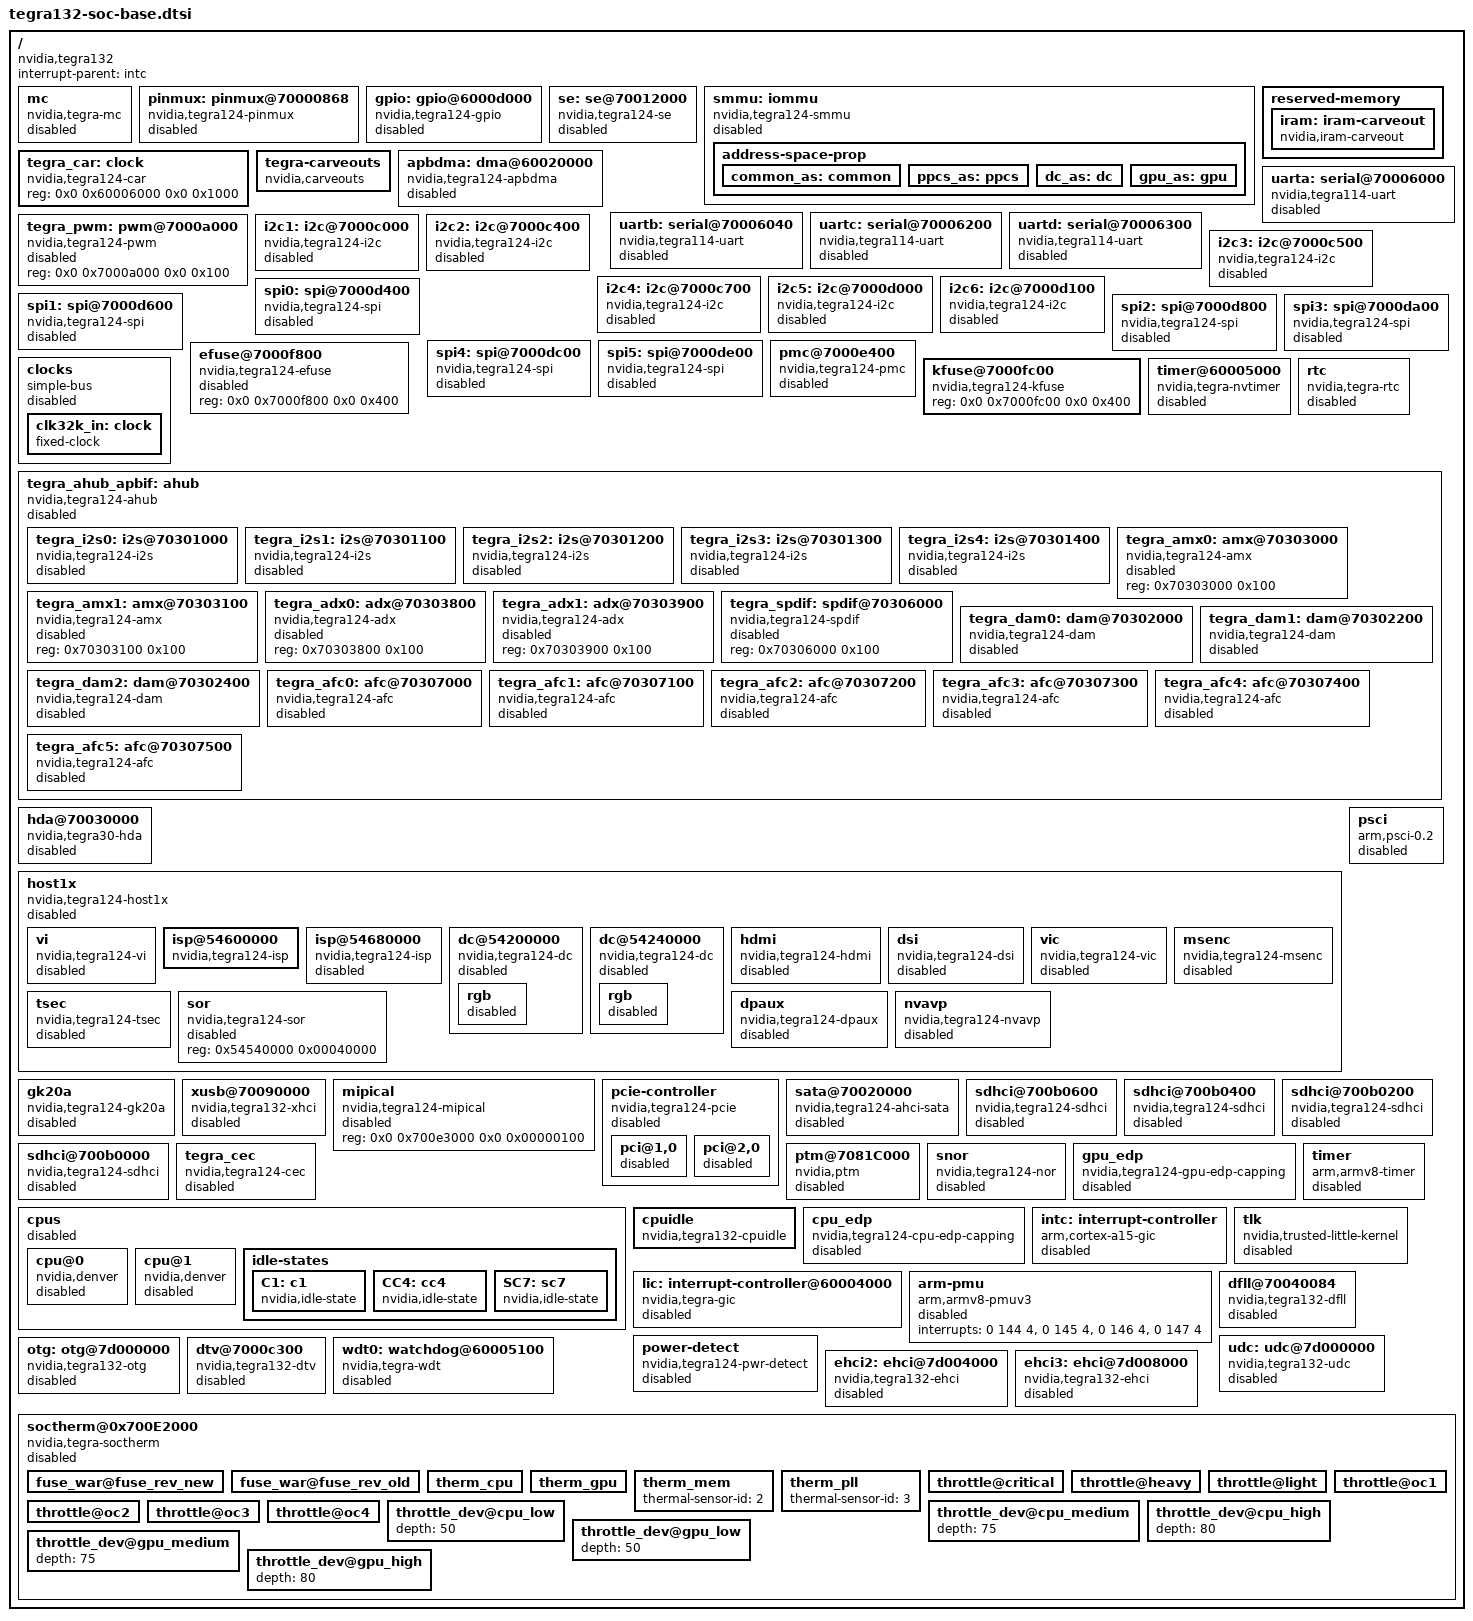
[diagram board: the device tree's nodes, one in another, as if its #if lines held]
/*
 * tegra132-soc-base.dtsi: SOC specific DTSI file with all node disabled.
 *
 * Copyright (c) 2013-2015, NVIDIA CORPORATION. All rights reserved.
 *
 * This program is free software; you can redistribute it and/or modify it
 * under the terms and conditions of the GNU General Public License,
 * version 2, as published by the Free Software Foundation.
 *
 * This program is distributed in the hope it will be useful, but WITHOUT
 * ANY WARRANTY; without even the implied warranty of MERCHANTABILITY or
 * FITNESS FOR A PARTICULAR PURPOSE.  See the GNU General Public License for
 * more details.
 */

#include <dt-bindings/gpio/tegra-gpio.h>
#include <dt-bindings/input/input.h>
#include <dt-bindings/interrupt-controller/arm-gic.h>
#include <dt-bindings/memory/tegra-swgroup.h>
#include <dt-bindings/soc/nvidia,tegra132-powergate.h>
#include "tegra132-platforms/tegra132-prods.dtsi"
#include "tegra132-platforms/tegra132-soc-power-domain.dtsi"

#include "denver.dtsi"

#if defined(TEGRA132_PACKAGE_IS_DSC) ^ !defined(TEGRA132_PACKAGE_IS_MID)
#error please define either TEGRA132_PACKAGE_IS_DSC or TEGRA132_PACKAGE_IS_MID
#endif

/ {
	compatible = "nvidia,tegra132";
	interrupt-parent = <&intc>;
	#address-cells = <2>;
	#size-cells = <2>;

	mc {
		compatible = "nvidia,tegra-mc";

		reg-ranges = <9>; /* Per channel. */
		reg = <0x0 0x70019000 0x0 0x00c>,
		      <0x0 0x70019050 0x0 0x19c>,
		      <0x0 0x70019200 0x0 0x024>,
		      <0x0 0x7001929c 0x0 0x1b8>,
		      <0x0 0x70019464 0x0 0x198>,
		      <0x0 0x70019604 0x0 0x3b0>,
		      <0x0 0x700199bc 0x0 0x020>,
		      <0x0 0x700199f8 0x0 0x08c>,
		      <0x0 0x70019ab4 0x0 0x54c>;

		interrupts = <0 77 0x4>;
		int_count  = <8>;
		int_mask   = <0x13D40>;

		channels = <1>;
		status = "disabled";
	};

	pinmux: pinmux@70000868 {
		compatible = "nvidia,tegra124-pinmux";
		reg = <0x0 0x70000868 0x0 0x164		/* Pad control registers */
		       0x0 0x70003000 0x0 0x434		/* Mux registers */
		       0x0 0x70000820 0x0 0x8>;		/* MIPI pad control */
		#gpio-range-cells = <3>;
		status = "disabled";
	};

	gpio: gpio@6000d000 {
		compatible = "nvidia,tegra124-gpio", "nvidia,tegra30-gpio";
		reg = <0x0 0x6000d000 0x0 0x1000>;
		interrupts = <0 32 0x04
				0 33 0x04
				0 34 0x04
				0 35 0x04
				0 55 0x04
				0 87 0x04
				0 89 0x04
				0 125 0x04>;
		#gpio-cells = <2>;
		gpio-controller;
		#interrupt-cells = <2>;
		interrupt-controller;
		gpio-ranges = <&pinmux 0 0 251>;
		status = "disabled";
	};

	se: se@70012000 {
		compatible = "nvidia,tegra124-se";
		power-domains = <&mc_clk_pd>;
		reg = <0x0 0x70012000 0x0 0x2000 /* SE base */
			0x0 0x7000e400 0x0 0x400>; /* PMC base */
		interrupts = <0 58 0x04>;
		status = "disabled";
	};

	smmu: iommu {
		compatible = "nvidia,tegra124-smmu";
		reg = <0x0 0x70019000 0x0 0x1000
		       0x0 0x6000c000 0x0 0x1000>;
		status = "disabled";
		#asids = <128>;
		dma-window = <0x0 0x80000000 0x0 0x7ff00000>;
		#iommu-cells = <1>;
		swgid-mask = <0x1 0xfffecdcf>;
		#num-translation-enable = <4>;
		#num-asid-security = <8>;

		domains = <
			&ppcs_as TEGRA_SWGROUP_CELLS3(PPCS, PPCS1, PPCS2)
			&gpu_as TEGRA_SWGROUP_CELLS(GPUB)
			&dc_as TEGRA_SWGROUP_CELLS3(DC, DC12, DCB)
			&common_as TEGRA_SWGROUP_CELLS(AFI)
			&common_as TEGRA_SWGROUP_CELLS(SDMMC1A)
			&common_as TEGRA_SWGROUP_CELLS(SDMMC2A)
			&common_as TEGRA_SWGROUP_CELLS(SDMMC3A)
			&common_as TEGRA_SWGROUP_CELLS(SDMMC4A)
			&common_as 0xFFFFFFFF 0xFFFFFFFF>;

		address-space-prop {
			common_as: common {
				iova-start = <0x0 0x80000000>;
				iova-size = <0x0 0x7FF00000>;
				num-pf-page = <0>;
				gap-page = <1>;
			};
			ppcs_as: ppcs {
				iova-start = <0x0 0x80000000>;
				iova-size = <0x0 0x7FF00000>;
				num-pf-page = <1>;
				gap-page = <1>;
			};
			dc_as: dc {
				iova-start = <0x0 0x00010000>;
				iova-size = <0x0 0xFFFEFFFF>;
				num-pf-page = <0>;
				gap-page = <0>;
			};
			gpu_as: gpu {
				iova-start = <0x0 0x00100000>;
				iova-size = <0x0 0xFFEFFFFF>;
				alignment = <0x20000>;
				num-pf-page = <0>;
				gap-page = <0>;
			};
		};
	};

	tegra_car: clock {
		compatible = "nvidia,tegra124-car";
		reg = <0x0 0x60006000 0x0 0x1000>;
		#clock-cells = <1>;
	};

	reserved-memory {
		#address-cells = <2>;
		#size-cells = <2>;
		ranges;

		iram: iram-carveout {
			compatible = "nvidia,iram-carveout";
			reg = <0x0 0x40001000 0x0 0x3F000>;
			no-map;
		};
	};

	tegra-carveouts {
		compatible = "nvidia,carveouts";
		iommus = <&smmu TEGRA_SWGROUP_HC>,
			 <&smmu TEGRA_SWGROUP_AVPC>;
		memory-region = <&iram>;
		status = "okay";
         };

	apbdma: dma@60020000 {
		compatible = "nvidia,tegra124-apbdma";
		power-domains = <&mc_clk_pd>;
		reg = <0x0 0x60020000 0x0 0x1400>;
		interrupts = <0 104 0x04
			      0 105 0x04
			      0 106 0x04
			      0 107 0x04
			      0 108 0x04
			      0 109 0x04
			      0 110 0x04
			      0 111 0x04
			      0 112 0x04
			      0 113 0x04
			      0 114 0x04
			      0 115 0x04
			      0 116 0x04
			      0 117 0x04
			      0 118 0x04
			      0 119 0x04
			      0 128 0x04
			      0 129 0x04
			      0 130 0x04
			      0 131 0x04
			      0 132 0x04
			      0 133 0x04
			      0 134 0x04
			      0 135 0x04
			      0 136 0x04
			      0 137 0x04
			      0 138 0x04
			      0 139 0x04
			      0 140 0x04
			      0 141 0x04
			      0 142 0x04
			      0 143 0x04>;
		#dma-cells = <1>;
		status = "disabled";
	};

	/*
	 * There are two serial driver i.e. 8250 based simple serial
	 * driver and APB DMA based serial driver for higher baudrate
	 * and performace. To enable the 8250 based driver, the compatible
	 * is "nvidia,tegra114-uart", "nvidia,tegra20-uart" and to enable
	 * the APB DMA based serial driver, the comptible is
	 * "nvidia,tegra114-hsuart", "nvidia,tegra30-hsuart".
	 */
	uarta: serial@70006000 {
		compatible = "nvidia,tegra114-uart", "nvidia,tegra20-uart";
		reg = <0x0 0x70006000 0x0 0x40>;
		reg-shift = <2>;
		interrupts = <0 36 0x04>;
		nvidia,dma-request-selector = <&apbdma 8>;
		iommus = <&smmu TEGRA_SWGROUP_PPCS>;
		status = "disabled";
		dmas = <&apbdma 8>, <&apbdma 8>;
		dma-names = "rx", "tx";
	};

	uartb: serial@70006040 {
		compatible = "nvidia,tegra114-uart", "nvidia,tegra20-uart";
		reg = <0x0 0x70006040 0x0 0x40>;
		reg-shift = <2>;
		interrupts = <0 37 0x04>;
		nvidia,dma-request-selector = <&apbdma 9>;
		iommus = <&smmu TEGRA_SWGROUP_PPCS>;
		status = "disabled";
		dmas = <&apbdma 9>, <&apbdma 9>;
		dma-names = "rx", "tx";
	};

	uartc: serial@70006200 {
		compatible = "nvidia,tegra114-uart", "nvidia,tegra20-uart";
		reg = <0x0 0x70006200 0x0 0x40>;
		reg-shift = <2>;
		interrupts = <0 46 0x04>;
		nvidia,dma-request-selector = <&apbdma 10>;
		iommus = <&smmu TEGRA_SWGROUP_PPCS>;
		status = "disabled";
		dmas = <&apbdma 10>, <&apbdma 10>;
		dma-names = "rx", "tx";
	};

	uartd: serial@70006300 {
		compatible = "nvidia,tegra114-uart", "nvidia,tegra20-uart";
		reg = <0x0 0x70006300 0x0 0x40>;
		reg-shift = <2>;
		interrupts = <0 90 0x04>;
		nvidia,dma-request-selector = <&apbdma 19>;
		iommus = <&smmu TEGRA_SWGROUP_PPCS>;
		status = "disabled";
		dmas = <&apbdma 19>, <&apbdma 19>;
		dma-names = "rx", "tx";
	};

	tegra_pwm: pwm@7000a000 {
		compatible = "nvidia,tegra124-pwm";
		reg = <0x0 0x7000a000 0x0 0x100>;
		#pwm-cells = <2>;
		status = "disabled";
	};

	i2c1: i2c@7000c000 {
		#address-cells = <1>;
		#size-cells = <0>;
		compatible = "nvidia,tegra124-i2c";
		reg = <0x0 0x7000c000 0x0 0x100>;
		interrupts = <0 38 0x04>;
		scl-gpio = <&gpio 20 0>; /* gpio PC4 */
		sda-gpio = <&gpio 21 0>; /* gpio PC5 */
		iommus = <&smmu TEGRA_SWGROUP_PPCS>;
		status = "disabled";
		clock-frequency = <400000>;
	};

	i2c2: i2c@7000c400 {
		#address-cells = <1>;
		#size-cells = <0>;
		compatible = "nvidia,tegra124-i2c";
		reg = <0x0 0x7000c400 0x0 0x100>;
		interrupts = <0 84 0x04>;
		scl-gpio = <&gpio 157 0>; /* gpio PT5 */
		sda-gpio = <&gpio 158 0>; /* gpio PT6 */
		iommus = <&smmu TEGRA_SWGROUP_PPCS>;
		status = "disabled";
		clock-frequency = <100000>;
	};

	i2c3: i2c@7000c500 {
		#address-cells = <1>;
		#size-cells = <0>;
		compatible = "nvidia,tegra124-i2c";
		reg = <0x0 0x7000c500 0x0 0x100>;
		interrupts = <0 92 0x04>;
		scl-gpio = <&gpio 217 0>; /* gpio PBB1 */
		sda-gpio = <&gpio 218 0>; /* gpio PBB2 */
		iommus = <&smmu TEGRA_SWGROUP_PPCS>;
		status = "disabled";
		clock-frequency = <400000>;
	};

	i2c4: i2c@7000c700 {
		#address-cells = <1>;
		#size-cells = <0>;
		compatible = "nvidia,tegra124-i2c";
		reg = <0x0 0x7000c700 0x0 0x100>;
		interrupts = <0 120 0x04>;
		scl-gpio = <&gpio 172 0>; /* gpio PV4 */
		sda-gpio = <&gpio 173 0>; /* gpio PV5 */
		iommus = <&smmu TEGRA_SWGROUP_PPCS>;
		status = "disabled";
		clock-frequency = <100000>;
	};

	i2c5: i2c@7000d000 {
		#address-cells = <1>;
		#size-cells = <0>;
		compatible = "nvidia,tegra124-i2c";
		reg = <0x0 0x7000d000 0x0 0x100>;
		interrupts = <0 53 0x04>;
		nvidia,require-cldvfs-clock;
		scl-gpio = <&gpio 206 0>; /* gpio PZ6 */
		sda-gpio = <&gpio 207 0>; /* gpio PZ7 */
		iommus = <&smmu TEGRA_SWGROUP_PPCS>;
		status = "disabled";
		clock-frequency = <400000>;
	};

	i2c6: i2c@7000d100 {
		#address-cells = <1>;
		#size-cells = <0>;
		compatible = "nvidia,tegra124-i2c";
		reg = <0x0 0x7000d100 0x0 0x100>;
		interrupts = <0 63 0x04>;
		iommus = <&smmu TEGRA_SWGROUP_PPCS>;
		status = "disabled";
		clock-frequency = <400000>;
	};

	spi0: spi@7000d400 {
		compatible = "nvidia,tegra124-spi";
		reg = <0x0 0x7000d400 0x0 0x200>;
		interrupts = <0 59 0x04>;
		nvidia,dma-request-selector = <&apbdma 15>;
		iommus = <&smmu TEGRA_SWGROUP_PPCS>;
		#address-cells = <1>;
		#size-cells = <0>;
		clocks = <&tegra_car 41>;
		status = "disabled";
		dmas = <&apbdma 15>, <&apbdma 15>;
		dma-names = "rx", "tx";
		nvidia,clk-parents = "pll_p", "clk_m";
	};

	spi1: spi@7000d600 {
		compatible = "nvidia,tegra124-spi";
		reg = <0x0 0x7000d600 0x0 0x200>;
		interrupts = <0 82 0x04>;
		nvidia,dma-request-selector = <&apbdma 16>;
		iommus = <&smmu TEGRA_SWGROUP_PPCS>;
		#address-cells = <1>;
		#size-cells = <0>;
		clocks = <&tegra_car 44>;
		status = "disabled";
		dmas = <&apbdma 16>, <&apbdma 16>;
		dma-names = "rx", "tx";
		nvidia,clk-parents = "pll_p", "clk_m";
	};

	spi2: spi@7000d800 {
		compatible = "nvidia,tegra124-spi";
		reg = <0x0 0x7000d800 0x0 0x200>;
		interrupts = <0 83 0x04>;
		nvidia,dma-request-selector = <&apbdma 17>;
		iommus = <&smmu TEGRA_SWGROUP_PPCS>;
		#address-cells = <1>;
		#size-cells = <0>;
		clocks = <&tegra_car 46>;
		status = "disabled";
		dmas = <&apbdma 17>, <&apbdma 17>;
		dma-names = "rx", "tx";
		nvidia,clk-parents = "pll_p", "clk_m";
	};

	spi3: spi@7000da00 {
		compatible = "nvidia,tegra124-spi";
		reg = <0x0 0x7000da00 0x0 0x200>;
		interrupts = <0 93 0x04>;
		nvidia,dma-request-selector = <&apbdma 18>;
		iommus = <&smmu TEGRA_SWGROUP_PPCS>;
		#address-cells = <1>;
		#size-cells = <0>;
		clocks = <&tegra_car 68>;
		status = "disabled";
		dmas = <&apbdma 18>, <&apbdma 18>;
		dma-names = "rx", "tx";
		nvidia,clk-parents = "pll_p", "clk_m";
	};

	spi4: spi@7000dc00 {
		compatible = "nvidia,tegra124-spi";
		reg = <0x0 0x7000dc00 0x0 0x200>;
		interrupts = <0 94 0x04>;
		nvidia,dma-request-selector = <&apbdma 27>;
		iommus = <&smmu TEGRA_SWGROUP_PPCS>;
		#address-cells = <1>;
		#size-cells = <0>;
		clocks = <&tegra_car 104>;
		status = "disabled";
		dmas = <&apbdma 27>, <&apbdma 27>;
		dma-names = "rx", "tx";
		nvidia,clk-parents = "pll_p", "clk_m";
	};

	spi5: spi@7000de00 {
		compatible = "nvidia,tegra124-spi";
		reg = <0x0 0x7000de00 0x0 0x200>;
		interrupts = <0 79 0x04>;
		nvidia,dma-request-selector = <&apbdma 28>;
		iommus = <&smmu TEGRA_SWGROUP_PPCS>;
		#address-cells = <1>;
		#size-cells = <0>;
		clocks = <&tegra_car 105>;
		status = "disabled";
		dmas = <&apbdma 28>, <&apbdma 28>;
		dma-names = "rx", "tx";
		nvidia,clk-parents = "pll_p", "clk_m";
	};

	pmc@7000e400 {
		compatible = "nvidia,tegra124-pmc";
		reg = <0x0 0x7000e400 0x0 0x400>;
		clocks = <&tegra_car 261>, <&clk32k_in>;
		clock-names = "pclk", "clk32k_in";
		status = "disabled";
	};

	efuse@7000f800 {
		compatible = "nvidia,tegra124-efuse";
		reg = <0x0 0x7000f800 0x0 0x400>;
		status = "disabled";
	};

	kfuse@7000fc00 {
		compatible = "nvidia,tegra124-kfuse";
		reg = <0x0 0x7000fc00 0x0 0x400>;
		status = "okay";
	};

	clocks {
		compatible = "simple-bus";
		#address-cells = <1>;
		#size-cells = <0>;
		status = "disabled";

		clk32k_in: clock {
			compatible = "fixed-clock";
			reg=<0>;
			#clock-cells = <0>;
			clock-frequency = <32768>;
		};
	};

	timer@60005000 {
		compatible = "nvidia,tegra-nvtimer";
		reg = <0x0 0x60005000 0x0 0x400>;
		interrupts = <0 0 0x04
			      0 1 0x04
			      0 41 0x04
			      0 42 0x04
			      0 121 0x04
			      0 151 0x04
			      0 152 0x04
			      0 153 0x04
			      0 154 0x04
			      0 155 0x04
			      0 122 0x04>;
		clocks = <&tegra_car 5>;
		status = "disabled";
	};

	rtc {
		compatible = "nvidia,tegra-rtc";
		reg = <0x0 0x7000e000 0x0 0x100>;
		interrupts = <0 2 0x04>;
		clocks = <&tegra_car 4>;
		status = "disabled";
	};

	tegra_ahub_apbif: ahub {
		compatible = "nvidia,tegra124-ahub";
		reg = <0x0 0x70300000 0x0 0x200>,
			<0x0 0x70300800 0x0 0x800>,
			<0x0 0x70300200 0x0 0x200>;
		interrupts = <0 103 0x04>;
		dmas = <&apbdma 1>, <&apbdma 1>, <&apbdma 2>, <&apbdma 2>,
			<&apbdma 3>, <&apbdma 3>, <&apbdma 4>, <&apbdma 4>,
			<&apbdma 6>, <&apbdma 6>, <&apbdma 7>, <&apbdma 7>,
			<&apbdma 12>, <&apbdma 12>, <&apbdma 13>, <&apbdma 13>,
			<&apbdma 14>, <&apbdma 14>, <&apbdma 29>, <&apbdma 29>;
		dma-names = "rx0", "tx0", "rx1", "tx1", "rx2", "tx2",
				"rx3", "tx3", "rx4", "tx4", "rx5", "tx5",
				"rx6", "tx6", "rx7", "tx7", "rx8", "tx8",
				"rx9", "tx9";
		status = "disabled";

		#address-cells = <1>;
		#size-cells = <1>;

		ranges = <0x70300000 0x0 0x70300000 0x00010000>;

		tegra_i2s0: i2s@70301000 {
			compatible = "nvidia,tegra124-i2s";
			reg = <0x70301000 0x100>;
			interrupts = <0 103 0x04>;
			nvidia,ahub-cif-ids = <4 4>;
			nvidia,ahub-i2s-id = <0>;
			status = "disabled";
		};

		tegra_i2s1: i2s@70301100 {
			compatible = "nvidia,tegra124-i2s";
			reg = <0x70301100 0x100>;
			interrupts = <0 103 0x04>;
			nvidia,ahub-cif-ids = <5 5>;
			nvidia,ahub-i2s-id = <1>;
			status = "disabled";
		};

		tegra_i2s2: i2s@70301200 {
			compatible = "nvidia,tegra124-i2s";
			reg = <0x70301200 0x100>;
			interrupts = <0 103 0x04>;
			nvidia,ahub-cif-ids = <6 6>;
			nvidia,ahub-i2s-id = <2>;
			status = "disabled";
		};

		tegra_i2s3: i2s@70301300 {
			compatible = "nvidia,tegra124-i2s";
			reg = <0x70301300 0x100>;
			interrupts = <0 103 0x04>;
			nvidia,ahub-cif-ids = <7 7>;
			nvidia,ahub-i2s-id = <3>;
			status = "disabled";
		};

		tegra_i2s4: i2s@70301400 {
			compatible = "nvidia,tegra124-i2s";
			reg = <0x70301400 0x100>;
			interrupts = <0 103 0x04>;
			nvidia,ahub-cif-ids = <8 8>;
			nvidia,ahub-i2s-id = <4>;
			status = "disabled";
		};

		tegra_amx0: amx@70303000 {
			compatible = "nvidia,tegra124-amx";
			reg = <0x70303000 0x100>;
			status = "disabled";
		};

		tegra_amx1: amx@70303100 {
			compatible = "nvidia,tegra124-amx";
			reg = <0x70303100 0x100>;
			status = "disabled";
		};

		tegra_adx0: adx@70303800 {
			compatible = "nvidia,tegra124-adx";
			reg = <0x70303800 0x100>;
			status = "disabled";
		};

		tegra_adx1: adx@70303900 {
			compatible = "nvidia,tegra124-adx";
			reg = <0x70303900 0x100>;
			status = "disabled";
		};

		tegra_spdif: spdif@70306000 {
			compatible = "nvidia,tegra124-spdif";
			reg = <0x70306000 0x100>;
			status = "disabled";
		};

		tegra_dam0: dam@70302000 {
			compatible = "nvidia,tegra124-dam";
			reg = <0x70302000 0x200>;
			nvidia,ahub-dam-id = <0>;
			status = "disabled";
		};

		tegra_dam1: dam@70302200 {
			compatible = "nvidia,tegra124-dam";
			reg = <0x70302200 0x200>;
			nvidia,ahub-dam-id = <1>;
			status = "disabled";
		};

		tegra_dam2: dam@70302400 {
			compatible = "nvidia,tegra124-dam";
			reg = <0x70302400 0x200>;
			nvidia,ahub-dam-id = <2>;
			status = "disabled";
		};

		tegra_afc0: afc@70307000 {
			compatible = "nvidia,tegra124-afc";
			reg = <0x70307000 0x100>;
			nvidia,ahub-afc-id = <0>;
			status = "disabled";
		};

		tegra_afc1: afc@70307100 {
			compatible = "nvidia,tegra124-afc";
			reg = <0x70307100 0x100>;
			nvidia,ahub-afc-id = <1>;
			status = "disabled";
		};

		tegra_afc2: afc@70307200 {
			compatible = "nvidia,tegra124-afc";
			reg = <0x70307200 0x100>;
			nvidia,ahub-afc-id = <2>;
			status = "disabled";
		};

		tegra_afc3: afc@70307300 {
			compatible = "nvidia,tegra124-afc";
			reg = <0x70307300 0x100>;
			nvidia,ahub-afc-id = <3>;
			status = "disabled";
		};

		tegra_afc4: afc@70307400 {
			compatible = "nvidia,tegra124-afc";
			reg = <0x70307400 0x100>;
			nvidia,ahub-afc-id = <4>;
			status = "disabled";
		};

		tegra_afc5: afc@70307500 {
			compatible = "nvidia,tegra124-afc";
			reg = <0x70307500 0x100>;
			nvidia,ahub-afc-id = <5>;
			status = "disabled";
		};
	};

	hda@70030000 {
		compatible = "nvidia,tegra30-hda";
		power-domains = <&mc_clk_pd>;
		reg = <0x0 0x70030000 0x0 0x10000>;
		interrupts = <0 81 0x04>;
		status = "disabled";
	};

	host1x: host1x {
		compatible = "nvidia,tegra124-host1x", "simple-bus";
		power-domains = <&host1x_pd>;
		wakeup-capable;
		reg = <0x0 0x50000000 0x0 0x00034000>;
		interrupts = <0 65 0x04   /* mpcore syncpt */
			      0 67 0x04>; /* mpcore general */
		iommus = <&smmu TEGRA_SWGROUP_EPP>,
			 <&smmu TEGRA_SWGROUP_HC>,
			 <&smmu TEGRA_SWGROUP_HDA>,
			 <&smmu TEGRA_SWGROUP_VDE>;

		#address-cells = <1>;
		#size-cells = <1>;
		status = "disabled";

		ranges = <0x53000000 0x0 0x53000000 0x06000000>,
			 <0x60001000 0x0 0x60001000 0x0000e200>;

		vi {
			compatible = "nvidia,tegra124-vi";
			power-domains = <&ve_pd>;
			reg = <0x54080000 0x00040000>;
			interrupts = <0 69 0x04>;
			iommus = <&smmu TEGRA_SWGROUP_VI>;
			status = "disabled";
		};

		isp@54600000 {
			compatible = "nvidia,tegra124-isp";
			power-domains = <&ve_pd>;
			reg = <0x54600000 0x00040000>;
			interrupts = <0 71 0x04>;
			iommus = <&smmu TEGRA_SWGROUP_ISP>,
				 <&smmu TEGRA_SWGROUP_ISP2B>;
		};

		isp@54680000 {
			compatible = "nvidia,tegra124-isp";
			power-domains = <&ve_pd>;
			reg = <0x54680000 0x00040000>;
			interrupts = <0 70 0x04>;
			iommus = <&smmu TEGRA_SWGROUP_ISP>,
				 <&smmu TEGRA_SWGROUP_ISP2B>;
			status = "disabled";
		};

		dc@54200000 {
			compatible = "nvidia,tegra124-dc";
			power-domains = <&mc_clk_pd>;
			reg = <0x54200000 0x00040000>;
			interrupts = <0 73 0x04>;
			iommus = <&smmu TEGRA_SWGROUP_DC>,
				 <&smmu TEGRA_SWGROUP_DC12>;
			status = "disabled";

			rgb {
				status = "disabled";
			};
		};

		dc@54240000 {
			compatible = "nvidia,tegra124-dc";
			power-domains = <&mc_clk_pd>;
			reg = <0x54240000 0x00040000>;
			interrupts = <0 74 0x04>;
			iommus = <&smmu TEGRA_SWGROUP_DCB>;
			status = "disabled";

			rgb {
				status = "disabled";
			};
		};

		hdmi {
			compatible = "nvidia,tegra124-hdmi";
			reg = <0x54280000 0x00040000>;
			interrupts = <0 75 0x04>;
			status = "disabled";
		};

		dsi {
			compatible = "nvidia,tegra124-dsi";
			reg = <0x54300000 0x00040000
			       0x54400000 0x00040000>;
			status = "disabled";
		};

		vic {
			compatible = "nvidia,tegra124-vic";
			power-domains = <&vic03_pd>;
			reg = <0x54340000 0x00040000>;
			iommus = <&smmu TEGRA_SWGROUP_VIC>;
			status = "disabled";
		};

		msenc {
			compatible = "nvidia,tegra124-msenc";
			power-domains = <&msenc_pd>;
			reg = <0x544c0000 0x00040000>;
			iommus = <&smmu TEGRA_SWGROUP_MSENC>;
			status = "disabled";
		};

		tsec {
			compatible = "nvidia,tegra124-tsec";
			power-domains = <&tsec_pd>;
			reg = <0x54500000 0x00040000>;
			iommus = <&smmu TEGRA_SWGROUP_TSEC>;
			status = "disabled";
		};

		sor {
			compatible = "nvidia,tegra124-sor";
			reg = <0x54540000 0x00040000>;
			status = "disabled";
		};

		dpaux {
			compatible = "nvidia,tegra124-dpaux";
			reg = <0x545c0000 0x00040000>;
			interrupts = <0 159 0x4>; /* INT_DPAUX */
			status = "disabled";
		};

		nvavp {
			compatible = "nvidia,tegra124-nvavp";
			power-domains = <&nvavp_pd>;
			interrupts = <0 4 0x04>; /* mailbox AVP IRQ */
			reg = <0x60001000 0x0000e200>;
			status = "disabled";
		};
	};

	gk20a {
		compatible = "nvidia,tegra124-gk20a", "nvidia,gk20a";
		nvidia,host1x = <&host1x>;
		reg = <0x0 0x57000000 0x0 0x01000000>,
		      <0x0 0x58000000 0x0 0x01000000>,
		      <0x0 0x538F0000 0x0 0x00001000>;
		interrupts = <GIC_SPI 157 IRQ_TYPE_LEVEL_HIGH>,
			     <GIC_SPI 158 IRQ_TYPE_LEVEL_HIGH>;
		interrupt-names = "stall", "nonstall";
		resets = <&tegra_car 184>;
		reset-names = "gpu";
		iommus = <&smmu TEGRA_SWGROUP_GPUB>;
		access-vpr-phys;
		status = "disabled";
	};

	xusb@70090000 {
		compatible = "nvidia,tegra124-xhci";
		power-domains = <&mc_clk_pd>;
		reg = <0x0 0x70090000 0x0 0x8000
		       0x0 0x70098000 0x0 0x1000
		       0x0 0x70099000 0x0 0x1000
		       0x0 0x7009F000 0x0 0x1000>;
		interrupts = <0 39 0x04
			      0 40 0x04
			      0 49 0x04
			      0 97 0x04
			      0 21 0x04>;
		status = "disabled";
	};

	mipical {
		compatible = "nvidia,tegra124-mipical";
		reg = <0x0 0x700e3000 0x0 0x00000100>;
		status = "disabled";
	};

	pcie-controller {
		compatible = "nvidia,tegra124-pcie";
		power-domains = <&pcie_pd>;
		device_type = "pci";
		reg = <0x0 0x01003000 0x0 0x00000800   /* PADS registers */
		       0x0 0x01003800 0x0 0x00000800   /* AFI registers */
		       0x0 0x02000000 0x0 0x10000000>; /* configuration space */
		reg-names = "pads", "afi", "cs";
		interrupts = <GIC_SPI 98 IRQ_TYPE_LEVEL_HIGH>, /* controller interrupt */
			     <GIC_SPI 99 IRQ_TYPE_LEVEL_HIGH>; /* MSI interrupt */
		interrupt-names = "intr", "msi";

		#interrupt-cells = <1>;
		interrupt-map-mask = <0 0 0 0>;
		interrupt-map = <0 0 0 0 &intc GIC_SPI 98 IRQ_TYPE_LEVEL_HIGH>;

		bus-range = <0x00 0xff>;
		#address-cells = <3>;
		#size-cells = <2>;

		ranges = <0x82000000 0 0x01000000 0x0 0x01000000 0 0x00001000   /* port 0 configuration space */
			  0x82000000 0 0x01001000 0x0 0x01001000 0 0x00001000   /* port 1 configuration space */
			  0x81000000 0 0x0        0x0 0x12000000 0 0x00010000   /* downstream I/O (64 KiB) */
			  0x82000000 0 0x13000000 0x0 0x13000000 0 0x0d000000   /* non-prefetchable memory (208 MiB) */
			  0xc2000000 0 0x20000000 0x0 0x20000000 0 0x20000000>; /* prefetchable memory (512 MiB) */

		status = "disabled";

		pci@1,0 {
			device_type = "pci";
			assigned-addresses = <0x82000800 0 0x01000000 0 0x1000>;
			reg = <0x000800 0 0 0 0>;
			status = "disabled";

			#address-cells = <3>;
			#size-cells = <2>;
			ranges;

			nvidia,num-lanes = <4>;
		};

		pci@2,0 {
			device_type = "pci";
			assigned-addresses = <0x82001000 0 0x01001000 0 0x1000>;
			reg = <0x001000 0 0 0 0>;
			status = "disabled";

			#address-cells = <3>;
			#size-cells = <2>;
			ranges;

			nvidia,num-lanes = <1>;
		};

	};

	sata@70020000 {
		compatible = "nvidia,tegra124-ahci-sata";
		reg = <0x0 0x70021000 0x0 0x00001000>,
			<0x0 0x70027000 0x0 0x00002000>;
		interrupts = <0 23 0x04>;
		status = "disabled";
	};

	psci {
		compatible = "arm,psci";
		method = "smc";
		cpu_suspend = <0x84000001>;
		cpu_on = <0x84000003>;
		status = "disabled";
	};

	sdhci@700b0600 {
		compatible = "nvidia,tegra124-sdhci";
		power-domains = <&mc_clk_pd>;
		reg = <0x0 0x700b0600 0x0 0x200>;
		interrupts = < 0 31 0x04 >;
		iommus = <&smmu TEGRA_SWGROUP_SDMMC4A>;
		status = "disabled";
	};
	sdhci@700b0400 {
		compatible = "nvidia,tegra124-sdhci";
		power-domains = <&mc_clk_pd>;
		reg = <0x0 0x700b0400 0x0 0x200>;
		interrupts = < 0 19 0x04 >;
		iommus = <&smmu TEGRA_SWGROUP_SDMMC3A>;
		status = "disabled";
	};
	sdhci@700b0200 {
		compatible = "nvidia,tegra124-sdhci";
		power-domains = <&mc_clk_pd>;
		reg = <0x0 0x700b0200 0x0 0x200>;
		interrupts = < 0 15 0x04 >;
		iommus = <&smmu TEGRA_SWGROUP_SDMMC2A>;
		status = "disabled";
	};
	sdhci@700b0000 {
		compatible = "nvidia,tegra124-sdhci";
		power-domains = <&mc_clk_pd>;
		reg = <0x0 0x700b0000 0x0 0x200>;
		interrupts = < 0 14 0x04 >;
		iommus = <&smmu TEGRA_SWGROUP_SDMMC1A>;
		status = "disabled";
	};

	tegra_cec {
		compatible = "nvidia,tegra124-cec";
		reg = <0x0 0x70015000 0x0 0x00001000>;
		interrupts = <0 3 0x04>;
		status = "disabled";
	};

	ptm@7081C000 {
		compatible = "nvidia,ptm";
		reg = <0x0 0x7081c000 0x0 0x1000>, /* ptm0 */
		<0x0 0x7081d000 0x0 0x1000>, /* ptm1 */
		<0x0 0x7081e000 0x0 0x1000>, /* ptm2 */
		<0x0 0x7081f000 0x0 0x1000>, /* ptm3 */
		<0x0 0x70801000 0x0 0x1000>, /* etb */
		<0x0 0x70803000 0x0 0x1000>, /* tpiu */
		<0x0 0x70804000 0x0 0x1000>; /* funnel */
		status = "disabled";
	};

	snor {
		compatible = "nvidia,tegra124-nor";
		reg = <0x0 0x70009000 0x0 0x1000>;
		interrupts = <0 96 0x4>;
		status = "disabled";
	};

	gpu_edp {
		compatible = "nvidia,tegra124-gpu-edp-capping";
		status = "disabled";
		nvidia,freq_step = <12000000>;
		nvidia,edp_clk = "gbus";
		nvidia,edp_cap_clk = "edp.gbus";
		nvidia,tegra-ppm-cdyn = <10646000>;
		nvidia,tegra-ppm-min_leakage = <30>;
		nvidia,tegra-ppm-leakage_coeffs = <
			(  -208796792) (   37746202) (  -9648869) (   725660)
			(   704446675) ( -133808535) (  34470023) ( -2464142)
			(  -783701649) (  146557393) ( -38623024) (  2654269)
			(   292709580) (  -51246839) (  13984499) (  -934964)
			(   115095343) (  -65602614) (  11251896) (  -838394)
			(  -394753929) (  263095142) ( -49006854) (  3326269)
			(   441644020) ( -313320338) (  61612126) ( -3916786)
			(  -164021554) (  118634317) ( -24406245) (  1517573)
			(   -38857760) (   12243796) (  -1964159) (   181232)
			(   143265078) (  -71110695) (  13985680) (  -917947)
			(  -171456530) (   98906114) ( -21261015) (  1216159)
			(    67437536) (  -40520060) (   9265259) (  -484818)
			(     1795940) (    -345535) (     83004) (   -20007)
			(    -8549105) (    6333235) (  -1479815) (   115441)
			(    12192546) (  -10880741) (   2632212) (  -161404)
			(    -5328587) (    4953756) (  -1215038) (    64556)
			>;

	};

	cpus {
		#address-cells = <2>;
		#size-cells = <0>;
		status = "disabled";

		cpu@0 {
			device_type = "cpu";
			compatible = "nvidia,denver", "arm,armv8";
			reg = <0x0 0x0>;
			enable-method = "psci";
			cpu-idle-states = <&C1 &CC4 &SC7>;
			status = "disabled";
		};

		cpu@1 {
			device_type = "cpu";
			compatible = "nvidia,denver", "arm,armv8";
			reg = <0x0 0x1>;
			enable-method = "psci";
			cpu-idle-states = <&C1 &CC4 &SC7>;
			status = "disabled";
		};

		idle-states {

			C1: c1 {
				compatible = "nvidia,idle-state";
				arm,psci-suspend-param = <0x0>;
				idle-state-name = "c1";
				wakeup-latency-us = <1>;
				min-residency-us = <1>;
				pmstate = <0x0>;
				status = "okay";
			};

			CC4: cc4 {
				compatible = "nvidia,idle-state";
				arm,psci-suspend-param = <0x0>;
				idle-state-name = "cc4";
				wakeup-latency-us = <500>;
				min-residency-us = <2000>;
				pmstate = <0x9>;
				status = "okay";
			};

			SC7: sc7 {
				compatible = "nvidia,idle-state";
				arm,psci-suspend-param = <0x201000D>;
				wakeup-latency-us = <5000>;
				min-residency-us = <10000>;
				idle-state-name = "sc7-vdd-soc-off";
				status = "okay";
			};
		};
	};

	cpuidle {
		compatible = "nvidia,tegra132-cpuidle";
	};

	psci {
		compatible = "arm,psci-0.2";
		method = "smc";
	};

	cpu_edp {
		compatible = "nvidia,tegra124-cpu-edp-capping";
		status = "disabled";
		nvidia,freq_step = <12750000>;
		nvidia,edp_clk = "cpu_g";
#ifdef TEGRA132_PACKAGE_IS_DSC
		nvidia,hard_cap = <2500000 2300000>;
#endif
		nvidia,tegra-ppm-cdyn = <3900000 5900000>;
		nvidia,tegra-ppm-leakage_weights = <1000 1000>;
		nvidia,tegra-ppm-min_leakage = <30>;
		nvidia,tegra-ppm-coeff_scale = <1000>;
		nvidia,tegra-ppm-leakage_coeffs = <
			(  37941815) ( -34693402) (  7820012) ( -441775)
			(-120688312) ( 110469778) (-24921798) ( 1406135)
			( 125400868) (-114967356) ( 25961411) (-1462457)
			( -42517654) (  39125172) ( -8844968) (  497219)
			( -50381367) (  44032432) ( -9833725) (  555725)
			( 160275950) (-139793882) ( 31257629) (-1764975)
			(-166543984) ( 144936902) (-32453803) ( 1830681)
			(  56516540) ( -49076991) ( 11008971) ( -619802)
			(  17384788) ( -15152169) (  3354364) ( -189265)
			( -55185216) (  48061420) (-10652770) (  601257)
			(  57179883) ( -49766548) ( 11046206) ( -623597)
			( -19334275) (  16829382) ( -3741212) (  211201)
			(  -1678751) (   1460723) (  -322310) (   18193)
			(   5323806) (  -4629524) (  1022876) (  -57779)
			(  -5509910) (   4788629) ( -1059681) (   59896)
			(   1861103) (  -1617204) (   358518) (  -20274)
		>;
	};

	intc: interrupt-controller {
		compatible = "arm,cortex-a15-gic";
		reg = <0x0 0x50041000 0x0 0x1000
		       0x0 0x50042000 0x0 0x0100>;
		interrupt-controller;
		#interrupt-cells = <3>;
		status = "disabled";
	};

	lic: interrupt-controller@60004000 {
		compatible = "nvidia,tegra-gic";
		interrupt-controller;
		num-ictrls = <0x5>;
		reg = <0x0 0x60004000 0x0 0x40>,
		      <0x0 0x60004100 0x0 0x40>,
		      <0x0 0x60004200 0x0 0x40>,
		      <0x0 0x60004300 0x0 0x40>,
		      <0x0 0x60004400 0x0 0x40>;
		status = "disabled";
	};

	timer {
		compatible = "arm,armv8-timer";
		interrupts = <1 13 0xff01>,
			     <1 14 0xff01>,
			     <1 11 0xff01>,
			     <1 10 0xff01>;
		clock-frequency = <12000000>;
		status = "disabled";
	};

	tlk {
		compatible = "nvidia,trusted-little-kernel";
		logger = "enabled";
		storage = "enabled";
		status = "disabled";
	};

	arm-pmu {
		compatible = "arm,armv8-pmuv3";
		interrupts = <0 144 4>,
			     <0 145 4>,
			     <0 146 4>,
			     <0 147 4>;
		status = "disabled";
	};

	dfll@70040084 {
		compatible = "nvidia,tegra132-dfll";
		reg = <0x0 0x70040084 0x0 0x40>,
		      <0x0 0x70110000 0x0 0x400>;
		out-clock-name="dfll_cpu";
		status = "disabled";
	};

	power-detect {
		compatible = "nvidia,tegra124-pwr-detect";
		status = "disabled";
	};

	udc: udc@7d000000 {
		compatible = "nvidia,tegra132-udc";
		reg = <0x0 0x7d000000 0x0 0x4000>;
		interrupts = <0 20 0x04>;
		status = "disabled";
	};

	otg: otg@7d000000 {
		compatible = "nvidia,tegra132-otg";
		power-domains = <&mc_clk_pd>;
		reg = <0x0 0x7d000000 0x0 0x4000>;
		interrupts = <0 20 0x04>;
		status = "disabled";
	};

	dtv@7000c300 {
		compatible = "nvidia,tegra132-dtv";
		reg = <0x0 0x7000c300 0x0 0x100>;
		nvidia,dma-request-selector = <11>;
		dmas = <&apbdma 11>;
		dma-names = "rx";
		status = "disabled";
	};

	sdhci@700b0600 {
		compatible = "nvidia,tegra124-sdhci";
		reg = <0x0 0x700b0600 0x0 0x200>;
		interrupts = < 0 31 0x04 >;
		status = "disabled";
	};

	sdhci@700b0400 {
		compatible = "nvidia,tegra124-sdhci";
		reg = <0x0 0x700b0400 0x0 0x200>;
		interrupts = < 0 19 0x04 >;
		status = "disabled";
	};

	sdhci@700b0200 {
		compatible = "nvidia,tegra124-sdhci";
		reg = <0x0 0x700b0200 0x0 0x200>;
		interrupts = < 0 15 0x04 >;
		status = "disabled";
	};

	sdhci@700b0000 {
		compatible = "nvidia,tegra124-sdhci";
		reg = <0x0 0x700b0000 0x0 0x200>;
		interrupts = < 0 14 0x04 >;
		status = "disabled";
	};
	/* WDT0 using TMR7 as timing reference */
	wdt0: watchdog@60005100 {
		compatible = "nvidia,tegra-wdt";
		reg = <0x0 0x60005180 0x0 0x20		/* WDT4 registers */
			0x0 0x60005070 0x0 0x8>;	/* TMR7 registers */
		interrupts = <0 123 0x04>;
		nvidia,expiry-count = <4>;
		status = "disabled";
	};

	sata@70020000 {
		compatible = "nvidia,tegra124-ahci-sata";
		reg = <0x0 0x70027000 0x0 0x00002000>,
			< 0x0 0x70021000 0x0 0x0001000>;
		interrupt = <0 23 0x04>;
		status = "disabled";
	};

	ehci2: ehci@7d004000 {
		compatible = "nvidia,tegra132-ehci";
		power-domains = <&mc_clk_pd>;
		reg = <0x0 0x7d004000 0x0 0x4000>;
		interrupts = <0 21 0x04>;
		nvidia,has-hostpc;
		nvidia,power-off-on-suspend;
		nvidia,is-intf-utmi;
		nvidia,remote-wakeup-supported;
		nvidia,hssync-start-delay = <0>;
		nvidia,idle-wait-delay = <17>;
		nvidia,elastic-limit = <16>;
		nvidia,term-range-adj = <6>;
		nvidia,xcvr-setup = <8>;
		nvidia,xcvr-lsfslew = <2>;
		nvidia,xcvr-lsrslew = <2>;
		nvidia,xcvr-use-fuses;
		nvidia,vbus-oc-map = <5>;
		nvidia,xcvr-setup-offset = <0>;
		status = "disabled";
	};

	ehci3: ehci@7d008000 {
		compatible = "nvidia,tegra132-ehci";
		power-domains = <&mc_clk_pd>;
		reg = <0x0 0x7d008000 0x0 0x4000>;
		interrupts = <0 97 0x04>;
		nvidia,has-hostpc;
		nvidia,power-off-on-suspend;
		nvidia,is-intf-utmi;
		nvidia,remote-wakeup-supported;
		nvidia,hssync-start-delay = <0>;
		nvidia,idle-wait-delay = <17>;
		nvidia,elastic-limit = <16>;
		nvidia,term-range-adj = <6>;
		nvidia,xcvr-setup = <8>;
		nvidia,xcvr-lsfslew = <2>;
		nvidia,xcvr-lsrslew = <2>;
		nvidia,xcvr-use-fuses;
		nvidia,vbus-oc-map = <5>;
		nvidia,xcvr-setup-offset = <0>;
		status = "disabled";
	};

	xusb@70090000 {
		compatible = "nvidia,tegra132-xhci";
	};

	soctherm@0x700E2000 {
		compatible = "nvidia,tegra-soctherm";
		reg =	<0x0 0x700E2000 0x0 0x600>, /* 0: SOC_THERM reg_base */
			<0x0 0x60006000 0x0 0x400>, /* 1: T124: CAR reg_base */
			<0x0 0x70040000 0x0 0x200>; /* 2: T132: CCROC reg_base */
		interrupts = <0 48 0x04
			      0 51 0x04>;
		#thermal-sensor-cells = <1>;
		status = "disabled";
		interrupt-controller;
		#interrupt-cells = <2>;
		soctherm-clock-frequency = <51000000>;
		tsensor-clock-frequency  = <400000>;
		sensor-params-tall       = <16300>;
		sensor-params-tiddq      = <1>;
		sensor-params-ten-count  = <1>;
		sensor-params-tsample    = <120>;
		sensor-params-pdiv       = <8>;
		sensor-params-tsamp-ate  = <480>;
		sensor-params-pdiv-ate   = <8>;
		fuse_war@fuse_rev_new {
			device_type = "fuse_war";
			match_fuse_rev = <0>; /* see xx_fuse_offsets.h */
			cpu0 = <1126600  (-9433500)>;
			cpu1 = <1110800  (-7383000)>;
			cpu2 = <1113800  (-6215200)>;
			cpu3 = <1129600  (-8196100)>;
			mem0 = <1132900  (-6755300)>;
			mem1 = <1142300  (-7374200)>;
			gpu  = <1125100  (-6350400)>;
			pllx = <1118100  (-8208800)>;
		};
		fuse_war@fuse_rev_old {
			device_type = "fuse_war";
			match_fuse_rev = <1 2>; /* see xx_fuse_offsets.h */
			cpu0 = <1119800   (-6330400)>;
			cpu1 = <1094100   (-3751800)>;
			cpu2 = <1108800   (-3835200)>;
			cpu3 = <1103200   (-5132100)>;
			mem0 = <1168400  (-11266000)>;
			mem1 = <1185600  (-10861000)>;
			gpu  = <1158500  (-10714000)>;
			pllx = <1150000  (-11899000)>;
		};

		/* thermctl - groups of sensors */
		therm_cpu {
			device_type = "thermctl";
			thermal-sensor-id = <0>;
			hotspot-offset = <10000>;
		};
		therm_gpu {
			device_type = "thermctl";
			thermal-sensor-id = <1>;
			hotspot-offset = <5000>;
		};
		therm_mem {
			device_type = "thermctl";
			thermal-sensor-id = <2>;
		};
		therm_pll {
			device_type = "thermctl";
			thermal-sensor-id = <3>;
		};

		/* throttlectl - hardware 'throttle' devices */
		throttle@critical {
			device_type = "throttlectl";
			cdev-type = "tegra-shutdown";
			cooling-min-state = <0>;
			cooling-max-state = <3>;
			#cooling-cells = <2>;
		};
		throttle@heavy {
			device_type = "throttlectl";
			cdev-type = "tegra-heavy";
			cooling-min-state = <0>;
			cooling-max-state = <3>;
			#cooling-cells = <2>;
			priority = <100>;
			throttle_dev = <&{/soctherm@0x700E2000/throttle_dev@cpu_high}
					&{/soctherm@0x700E2000/throttle_dev@gpu_high}>;
		};
		throttle@light {
			device_type = "throttlectl";
			cdev-type = "tegra-light";
			cooling-min-state = <0>;
			cooling-max-state = <3>;
			#cooling-cells = <2>;
			priority = <50>;
			throttle_dev = <&{/soctherm@0x700E2000/throttle_dev@cpu_low}
					&{/soctherm@0x700E2000/throttle_dev@gpu_low}>;
		};
		throttle@oc1 {
			device_type = "throttlectl";
			cooling-min-state = <0>;
			cooling-max-state = <3>;
			#cooling-cells = <2>;
			priority = <10>;
			throttle_dev = <&{/soctherm@0x700E2000/throttle_dev@cpu_medium}
					&{/soctherm@0x700E2000/throttle_dev@gpu_medium}>;
		};
		throttle@oc2 {
			device_type = "throttlectl";
			cooling-min-state = <0>;
			cooling-max-state = <3>;
			#cooling-cells = <2>;
			priority = <10>;
			throttle_dev = <&{/soctherm@0x700E2000/throttle_dev@cpu_medium}
					&{/soctherm@0x700E2000/throttle_dev@gpu_medium}>;
		};
		throttle@oc3 {
			device_type = "throttlectl";
			cooling-min-state = <0>;
			cooling-max-state = <3>;
			#cooling-cells = <2>;
			priority = <10>;
			throttle_dev = <&{/soctherm@0x700E2000/throttle_dev@cpu_medium}
					&{/soctherm@0x700E2000/throttle_dev@gpu_medium}>;
		};
		throttle@oc4 {
			device_type = "throttlectl";
			cooling-min-state = <0>;
			cooling-max-state = <3>;
			#cooling-cells = <2>;
			priority = <10>;
			throttle_dev = <&{/soctherm@0x700E2000/throttle_dev@cpu_medium}
					&{/soctherm@0x700E2000/throttle_dev@gpu_medium}>;
		};

		/* TODO - throttle_dev - pulse skip cfg and parse the phandles */
		throttle_dev@cpu_low {
			device_type = "throttle_dev";
			depth = <50>;
		};
		throttle_dev@cpu_medium {
			device_type = "throttle_dev";
			depth = <75>;
		};
		throttle_dev@cpu_high {
			device_type = "throttle_dev";
			depth = <80>;
		};
		throttle_dev@gpu_low {
			device_type = "throttle_dev";
			depth = <50>;
		};
		throttle_dev@gpu_medium {
			device_type = "throttle_dev";
			depth = <75>;
		};
		throttle_dev@gpu_high {
			device_type = "throttle_dev";
			depth = <80>;
		};
	};
};
